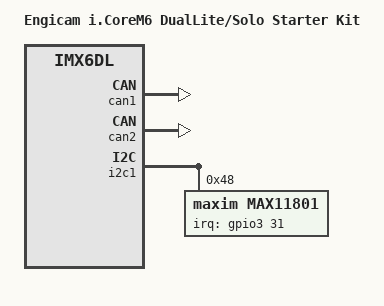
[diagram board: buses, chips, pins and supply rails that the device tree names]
// SPDX-License-Identifier: GPL-2.0 OR X11
/*
 * Copyright (C) 2016 Amarula Solutions B.V.
 * Copyright (C) 2016 Engicam S.r.l.
 */

/dts-v1/;

#include "imx6dl.dtsi"
#include "imx6qdl-icore.dtsi"

/ {
	model = "Engicam i.CoreM6 DualLite/Solo Starter Kit";
	compatible = "engicam,imx6-icore", "fsl,imx6dl";
};

&can1 {
	status = "okay";
};

&can2 {
	status = "okay";
};

&i2c1 {
	max11801: touchscreen@48 {
		compatible = "maxim,max11801";
		reg = <0x48>;
		interrupt-parent = <&gpio3>;
		interrupts = <31 IRQ_TYPE_EDGE_FALLING>;
	};
};
